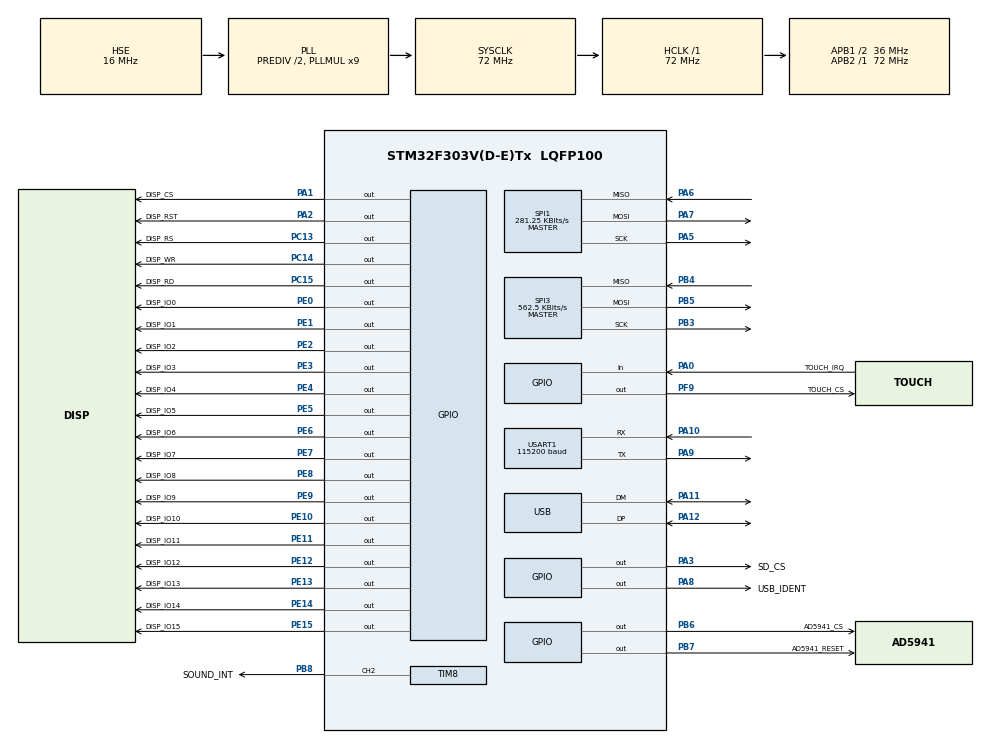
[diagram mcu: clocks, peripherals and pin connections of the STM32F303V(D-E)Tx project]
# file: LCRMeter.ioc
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ADC1.Channel-0\#ChannelRegularConversion=ADC_CHANNEL_VREFINT
ADC1.NbrOfConversionFlag=1
ADC1.Offset-0\#ChannelRegularConversion=0
ADC1.OffsetNumber-0\#ChannelRegularConversion=ADC_OFFSET_NONE
ADC1.Rank-0\#ChannelRegularConversion=1
ADC1.SamplingTime-0\#ChannelRegularConversion=ADC_SAMPLETIME_181CYCLES_5
ADC1.master=1
FREERTOS.MEMORY_ALLOCATION=2
FREERTOS.Tasks01=defaultTask,0,2048,StartDefaultTask,Default,NULL,Static,defaultTaskBuffer,defaultTaskControlBlock
FREERTOS.configTOTAL_HEAP_SIZE=35000
FREERTOS.configUSE_PREEMPTION=0
FREERTOS.configUSE_RECURSIVE_MUTEXES=1
Mcu.Family=STM32F3
Mcu.Name=STM32F303V(D-E)Tx
Mcu.Package=LQFP100
NVIC.PriorityGroup=NVIC_PRIORITYGROUP_4
NVIC.TIM6_DAC_IRQn=true\:0\:0\:false\:false\:true\:false\:false\:true
NVIC.TIM8_UP_IRQn=true\:1\:0\:true\:false\:true\:false\:true\:true
NVIC.TimeBase=TIM6_DAC_IRQn
NVIC.TimeBaseIP=TIM6
NVIC.USB_LP_CAN_RX0_IRQn=true\:5\:0\:false\:false\:true\:true\:false\:true
PA0.GPIO_Label=TOUCH_IRQ
PA0.Signal=GPIO_Input
PA1.GPIO_Label=DISP_CS
PA1.GPIO_Speed=GPIO_SPEED_FREQ_HIGH
PA1.PinState=GPIO_PIN_SET
PA1.Signal=GPIO_Output
PA10.Mode=Asynchronous
PA10.Signal=USART1_RX
PA11.Mode=Device
PA11.Signal=USB_DM
PA12.Mode=Device
PA12.Signal=USB_DP
PA13.Mode=Serial_Wire
PA13.Signal=SYS_JTMS-SWDIO
PA14.Mode=Serial_Wire
PA14.Signal=SYS_JTCK-SWCLK
PA2.GPIO_Label=DISP_RST
PA2.GPIO_Speed=GPIO_SPEED_FREQ_HIGH
PA2.Signal=GPIO_Output
PA3.GPIO_Label=SD_CS
PA3.GPIO_Speed=GPIO_SPEED_FREQ_HIGH
PA3.PinState=GPIO_PIN_SET
PA3.Signal=GPIO_Output
PA5.Mode=Full_Duplex_Master
PA5.Signal=SPI1_SCK
PA6.Mode=Full_Duplex_Master
PA6.Signal=SPI1_MISO
PA7.Mode=Full_Duplex_Master
PA7.Signal=SPI1_MOSI
PA8.GPIO_Label=USB_IDENT
PA8.GPIO_Speed=GPIO_SPEED_FREQ_LOW
PA8.Signal=GPIO_Output
PA9.Mode=Asynchronous
PA9.Signal=USART1_TX
PB3.Mode=Full_Duplex_Master
PB3.Signal=SPI3_SCK
PB4.Mode=Full_Duplex_Master
PB4.Signal=SPI3_MISO
PB5.Mode=Full_Duplex_Master
PB5.Signal=SPI3_MOSI
PB6.GPIO_Label=AD5941_CS
PB6.GPIO_Speed=GPIO_SPEED_FREQ_HIGH
PB6.PinState=GPIO_PIN_SET
PB6.Signal=GPIO_Output
PB7.GPIO_Label=AD5941_RESET
PB7.GPIO_Speed=GPIO_SPEED_FREQ_LOW
PB7.Signal=GPIO_Output
PB8.GPIO_Label=SOUND_INT
PB8.Signal=S_TIM8_CH2
PC13.GPIO_Label=DISP_RS
PC13.GPIO_Speed=GPIO_SPEED_FREQ_LOW
PC13.Signal=GPIO_Output
PC14-OSC32_IN.GPIO_Label=DISP_WR
PC14-OSC32_IN.GPIO_Speed=GPIO_SPEED_FREQ_LOW
PC14-OSC32_IN.Signal=GPIO_Output
PC15-OSC32_OUT.GPIO_Label=DISP_RD
PC15-OSC32_OUT.GPIO_Speed=GPIO_SPEED_FREQ_LOW
PC15-OSC32_OUT.Signal=GPIO_Output
PE0.GPIO_Label=DISP_IO0
PE0.GPIO_Speed=GPIO_SPEED_FREQ_HIGH
PE0.Signal=GPIO_Output
PE1.GPIO_Label=DISP_IO1
PE1.GPIO_Speed=GPIO_SPEED_FREQ_HIGH
PE1.Signal=GPIO_Output
PE10.GPIO_Label=DISP_IO10
PE10.GPIO_Speed=GPIO_SPEED_FREQ_HIGH
PE10.Signal=GPIO_Output
PE11.GPIO_Label=DISP_IO11
PE11.GPIO_Speed=GPIO_SPEED_FREQ_HIGH
PE11.Signal=GPIO_Output
PE12.GPIO_Label=DISP_IO12
PE12.GPIO_Speed=GPIO_SPEED_FREQ_HIGH
PE12.Signal=GPIO_Output
PE13.GPIO_Label=DISP_IO13
PE13.GPIO_Speed=GPIO_SPEED_FREQ_HIGH
PE13.Signal=GPIO_Output
PE14.GPIO_Label=DISP_IO14
PE14.GPIO_Speed=GPIO_SPEED_FREQ_HIGH
PE14.Signal=GPIO_Output
PE15.GPIO_Label=DISP_IO15
PE15.GPIO_Speed=GPIO_SPEED_FREQ_HIGH
PE15.Signal=GPIO_Output
PE2.GPIO_Label=DISP_IO2
PE2.GPIO_Speed=GPIO_SPEED_FREQ_HIGH
PE2.Signal=GPIO_Output
PE3.GPIO_Label=DISP_IO3
PE3.GPIO_Speed=GPIO_SPEED_FREQ_HIGH
PE3.Signal=GPIO_Output
PE4.GPIO_Label=DISP_IO4
PE4.GPIO_Speed=GPIO_SPEED_FREQ_HIGH
PE4.Signal=GPIO_Output
PE5.GPIO_Label=DISP_IO5
PE5.GPIO_Speed=GPIO_SPEED_FREQ_HIGH
PE5.Signal=GPIO_Output
PE6.GPIO_Label=DISP_IO6
PE6.GPIO_Speed=GPIO_SPEED_FREQ_HIGH
PE6.Signal=GPIO_Output
PE7.GPIO_Label=DISP_IO7
PE7.GPIO_Speed=GPIO_SPEED_FREQ_HIGH
PE7.Signal=GPIO_Output
PE8.GPIO_Label=DISP_IO8
PE8.GPIO_Speed=GPIO_SPEED_FREQ_HIGH
PE8.Signal=GPIO_Output
PE9.GPIO_Label=DISP_IO9
PE9.GPIO_Speed=GPIO_SPEED_FREQ_HIGH
PE9.Signal=GPIO_Output
PF0-OSC_IN.Mode=HSE-External-Oscillator
PF0-OSC_IN.Signal=RCC_OSC_IN
PF1-OSC_OUT.Mode=HSE-External-Oscillator
PF1-OSC_OUT.Signal=RCC_OSC_OUT
PF9.GPIO_Label=TOUCH_CS
PF9.GPIO_Speed=GPIO_SPEED_FREQ_HIGH
PF9.PinState=GPIO_PIN_SET
PF9.Signal=GPIO_Output
ProjectManager.HeapSize=0x200
ProjectManager.StackSize=0x400
ProjectManager.TargetToolchain=SW4STM32
RCC.AHBFreq_Value=72000000
RCC.APB1CLKDivider=RCC_HCLK_DIV2
RCC.APB1Freq_Value=36000000
RCC.APB1TimFreq_Value=72000000
RCC.APB2Freq_Value=72000000
RCC.APB2TimFreq_Value=72000000
RCC.CortexFreq_Value=72000000
RCC.HCLKFreq_Value=72000000
RCC.HSE_VALUE=16000000
RCC.HSI_VALUE=8000000
RCC.LSE_VALUE=32768
RCC.PLLDivider=RCC_PREDIV_DIV2
RCC.PLLMUL=RCC_PLL_MUL9
RCC.PRESCALERUSB=RCC_USBCLKSOURCE_PLL_DIV1_5
RCC.SYSCLKFreq_VALUE=72000000
RCC.SYSCLKSourceVirtual=RCC_SYSCLKSOURCE_PLLCLK
RCC.USBFreq_Value=48000000
SH.S_TIM8_CH2.0=TIM8_CH2,PWM Generation2 CH2
SPI1.BaudRatePrescaler=SPI_BAUDRATEPRESCALER_256
SPI1.CalculateBaudRate=281.25 KBits/s
SPI1.DataSize=SPI_DATASIZE_8BIT
SPI1.Direction=SPI_DIRECTION_2LINES
SPI1.Mode=SPI_MODE_MASTER
SPI1.VirtualType=VM_MASTER
SPI3.BaudRatePrescaler=SPI_BAUDRATEPRESCALER_64
SPI3.CalculateBaudRate=562.5 KBits/s
SPI3.DataSize=SPI_DATASIZE_8BIT
SPI3.Direction=SPI_DIRECTION_2LINES
SPI3.Mode=SPI_MODE_MASTER
SPI3.VirtualType=VM_MASTER
TIM8.Channel-PWM\ Generation2\ CH2=TIM_CHANNEL_2
TIM8.OCMode_PWM-PWM\ Generation2\ CH2=TIM_OCMODE_PWM1
TIM8.OCPolarity_2=TIM_OCPOLARITY_HIGH
TIM8.Period=999
TIM8.Prescaler=71
USART1.BaudRate=115200
USART1.VirtualMode-Asynchronous=VM_ASYNC
USB_DEVICE.CLASS_NAME_FS=CDC
USB_DEVICE.VirtualMode=Cdc
USB_DEVICE.VirtualModeFS=Cdc_FS
VP_ADC1_Vref_Input.Mode=IN-Vrefint
VP_FATFS_VS_Generic.Mode=User_defined
VP_FREERTOS_VS_CMSIS_V1.Mode=CMSIS_V1
VP_SYS_VS_tim6.Mode=TIM6
VP_TIM8_VS_ClockSourceINT.Mode=Internal
VP_USB_DEVICE_VS_USB_DEVICE_CDC_FS.Mode=CDC_FS
board=custom

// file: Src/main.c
/* USER CODE BEGIN Header */
/**
  ******************************************************************************
  * @file           : main.c
  * @brief          : Main program body
  ******************************************************************************
  * @attention
  *
  * <h2><center>&copy; Copyright (c) 2020 STMicroelectronics.
  * All rights reserved.</center></h2>
  *
  * This software component is licensed by ST under Ultimate Liberty license
  * SLA0044, the "License"; You may not use this file except in compliance with
  * the License. You may obtain a copy of the License at:
  *                             www.st.com/SLA0044
  *
  ******************************************************************************
  */
/* USER CODE END Header */

#include "main.h"
#include "cmsis_os.h"
#include "fatfs.h"
#include "usb_device.h"

ADC_HandleTypeDef hadc1;

SPI_HandleTypeDef hspi1;
SPI_HandleTypeDef hspi3;

TIM_HandleTypeDef htim8;

UART_HandleTypeDef huart1;

osThreadId defaultTaskHandle;
uint32_t defaultTaskBuffer[ 2048 ];
osStaticThreadDef_t defaultTaskControlBlock;

void SystemClock_Config(void);
static void MX_GPIO_Init(void);
static void MX_SPI1_Init(void);
static void MX_SPI3_Init(void);
static void MX_USART1_UART_Init(void);
static void MX_TIM8_Init(void);
static void MX_ADC1_Init(void);
void StartDefaultTask(void const * argument);

int main(void)
{

  /* MCU Configuration--------------------------------------------------------*/

  /* Reset of all peripherals, Initializes the Flash interface and the Systick. */
  HAL_Init();

  /* Configure the system clock */
  SystemClock_Config();

  /* Initialize all configured peripherals */
  MX_GPIO_Init();
  MX_SPI1_Init();
  MX_SPI3_Init();
  MX_USART1_UART_Init();
  MX_TIM8_Init();
  MX_ADC1_Init();
  /* USER CODE BEGIN 2 */
  HAL_Delay(100);
  display_Init();
  /* USER CODE END 2 */

  /* Create the thread(s) */
  /* definition and creation of defaultTask */
  osThreadStaticDef(defaultTask, StartDefaultTask, osPriorityNormal, 0, 2048, defaultTaskBuffer, &defaultTaskControlBlock);
  defaultTaskHandle = osThreadCreate(osThread(defaultTask), NULL);

  /* Start scheduler */
  osKernelStart();

  /* We should never get here as control is now taken by the scheduler */

  /* Infinite loop */
  while (1)
  {

  }
}

void SystemClock_Config(void)
{
  RCC_OscInitTypeDef RCC_OscInitStruct = {0};
  RCC_ClkInitTypeDef RCC_ClkInitStruct = {0};
  RCC_PeriphCLKInitTypeDef PeriphClkInit = {0};

  /** Initializes the CPU, AHB and APB busses clocks
  */
  RCC_OscInitStruct.OscillatorType = RCC_OSCILLATORTYPE_HSE;
  RCC_OscInitStruct.HSEState = RCC_HSE_ON;
  RCC_OscInitStruct.HSIState = RCC_HSI_ON;
  RCC_OscInitStruct.PLL.PLLState = RCC_PLL_ON;
  RCC_OscInitStruct.PLL.PLLSource = RCC_PLLSOURCE_HSE;
  RCC_OscInitStruct.PLL.PLLMUL = RCC_PLL_MUL9;
  RCC_OscInitStruct.PLL.PREDIV = RCC_PREDIV_DIV2;
  if (HAL_RCC_OscConfig(&RCC_OscInitStruct) != HAL_OK)
  {
    Error_Handler();
  }
  /** Initializes the CPU, AHB and APB busses clocks
  */
  RCC_ClkInitStruct.ClockType = RCC_CLOCKTYPE_HCLK|RCC_CLOCKTYPE_SYSCLK
                              |RCC_CLOCKTYPE_PCLK1|RCC_CLOCKTYPE_PCLK2;
  RCC_ClkInitStruct.SYSCLKSource = RCC_SYSCLKSOURCE_PLLCLK;
  RCC_ClkInitStruct.AHBCLKDivider = RCC_SYSCLK_DIV1;
  RCC_ClkInitStruct.APB1CLKDivider = RCC_HCLK_DIV2;
  RCC_ClkInitStruct.APB2CLKDivider = RCC_HCLK_DIV1;

  if (HAL_RCC_ClockConfig(&RCC_ClkInitStruct, FLASH_LATENCY_2) != HAL_OK)
  {
    Error_Handler();
  }
  PeriphClkInit.PeriphClockSelection = RCC_PERIPHCLK_USB|RCC_PERIPHCLK_USART1
                              |RCC_PERIPHCLK_TIM8|RCC_PERIPHCLK_ADC12;
  PeriphClkInit.Usart1ClockSelection = RCC_USART1CLKSOURCE_PCLK2;
  PeriphClkInit.Adc12ClockSelection = RCC_ADC12PLLCLK_DIV1;
  PeriphClkInit.USBClockSelection = RCC_USBCLKSOURCE_PLL_DIV1_5;
  PeriphClkInit.Tim8ClockSelection = RCC_TIM8CLK_HCLK;
  if (HAL_RCCEx_PeriphCLKConfig(&PeriphClkInit) != HAL_OK)
  {
    Error_Handler();
  }
}

static void MX_ADC1_Init(void)
{

  ADC_MultiModeTypeDef multimode = {0};
  ADC_ChannelConfTypeDef sConfig = {0};

  /** Common config
  */
  hadc1.Instance = ADC1;
  hadc1.Init.ClockPrescaler = ADC_CLOCK_ASYNC_DIV1;
  hadc1.Init.Resolution = ADC_RESOLUTION_12B;
  hadc1.Init.ScanConvMode = ADC_SCAN_DISABLE;
  hadc1.Init.ContinuousConvMode = DISABLE;
  hadc1.Init.DiscontinuousConvMode = DISABLE;
  hadc1.Init.ExternalTrigConvEdge = ADC_EXTERNALTRIGCONVEDGE_NONE;
  hadc1.Init.ExternalTrigConv = ADC_SOFTWARE_START;
  hadc1.Init.DataAlign = ADC_DATAALIGN_RIGHT;
  hadc1.Init.NbrOfConversion = 1;
  hadc1.Init.DMAContinuousRequests = DISABLE;
  hadc1.Init.EOCSelection = ADC_EOC_SINGLE_CONV;
  hadc1.Init.LowPowerAutoWait = DISABLE;
  hadc1.Init.Overrun = ADC_OVR_DATA_OVERWRITTEN;
  if (HAL_ADC_Init(&hadc1) != HAL_OK)
  {
    Error_Handler();
  }
  /** Configure the ADC multi-mode
  */
  multimode.Mode = ADC_MODE_INDEPENDENT;
  if (HAL_ADCEx_MultiModeConfigChannel(&hadc1, &multimode) != HAL_OK)
  {
    Error_Handler();
  }
  /** Configure Regular Channel
  */
  sConfig.Channel = ADC_CHANNEL_VREFINT;
  sConfig.Rank = ADC_REGULAR_RANK_1;
  sConfig.SingleDiff = ADC_SINGLE_ENDED;
  sConfig.SamplingTime = ADC_SAMPLETIME_181CYCLES_5;
  sConfig.OffsetNumber = ADC_OFFSET_NONE;
  sConfig.Offset = 0;
  if (HAL_ADC_ConfigChannel(&hadc1, &sConfig) != HAL_OK)
  {
    Error_Handler();
  }

}

static void MX_SPI1_Init(void)
{

  /* SPI1 parameter configuration*/
  hspi1.Instance = SPI1;
  hspi1.Init.Mode = SPI_MODE_MASTER;
  hspi1.Init.Direction = SPI_DIRECTION_2LINES;
  hspi1.Init.DataSize = SPI_DATASIZE_8BIT;
  hspi1.Init.CLKPolarity = SPI_POLARITY_LOW;
  hspi1.Init.CLKPhase = SPI_PHASE_1EDGE;
  hspi1.Init.NSS = SPI_NSS_SOFT;
  hspi1.Init.BaudRatePrescaler = SPI_BAUDRATEPRESCALER_256;
  hspi1.Init.FirstBit = SPI_FIRSTBIT_MSB;
  hspi1.Init.TIMode = SPI_TIMODE_DISABLE;
  hspi1.Init.CRCCalculation = SPI_CRCCALCULATION_DISABLE;
  hspi1.Init.CRCPolynomial = 7;
  hspi1.Init.CRCLength = SPI_CRC_LENGTH_DATASIZE;
  hspi1.Init.NSSPMode = SPI_NSS_PULSE_ENABLE;
  if (HAL_SPI_Init(&hspi1) != HAL_OK)
  {
    Error_Handler();
  }

}

static void MX_SPI3_Init(void)
{

  /* SPI3 parameter configuration*/
  hspi3.Instance = SPI3;
  hspi3.Init.Mode = SPI_MODE_MASTER;
  hspi3.Init.Direction = SPI_DIRECTION_2LINES;
  hspi3.Init.DataSize = SPI_DATASIZE_8BIT;
  hspi3.Init.CLKPolarity = SPI_POLARITY_LOW;
  hspi3.Init.CLKPhase = SPI_PHASE_1EDGE;
  hspi3.Init.NSS = SPI_NSS_SOFT;
  hspi3.Init.BaudRatePrescaler = SPI_BAUDRATEPRESCALER_64;
  hspi3.Init.FirstBit = SPI_FIRSTBIT_MSB;
  hspi3.Init.TIMode = SPI_TIMODE_DISABLE;
  hspi3.Init.CRCCalculation = SPI_CRCCALCULATION_DISABLE;
  hspi3.Init.CRCPolynomial = 7;
  hspi3.Init.CRCLength = SPI_CRC_LENGTH_DATASIZE;
  hspi3.Init.NSSPMode = SPI_NSS_PULSE_ENABLE;
  if (HAL_SPI_Init(&hspi3) != HAL_OK)
  {
    Error_Handler();
  }

}

static void MX_TIM8_Init(void)
{

  TIM_ClockConfigTypeDef sClockSourceConfig = {0};
  TIM_MasterConfigTypeDef sMasterConfig = {0};
  TIM_OC_InitTypeDef sConfigOC = {0};
  TIM_BreakDeadTimeConfigTypeDef sBreakDeadTimeConfig = {0};

  htim8.Instance = TIM8;
  htim8.Init.Prescaler = 71;
  htim8.Init.CounterMode = TIM_COUNTERMODE_UP;
  htim8.Init.Period = 999;
  htim8.Init.ClockDivision = TIM_CLOCKDIVISION_DIV1;
  htim8.Init.RepetitionCounter = 0;
  htim8.Init.AutoReloadPreload = TIM_AUTORELOAD_PRELOAD_DISABLE;
  if (HAL_TIM_Base_Init(&htim8) != HAL_OK)
  {
    Error_Handler();
  }
  sClockSourceConfig.ClockSource = TIM_CLOCKSOURCE_INTERNAL;
  if (HAL_TIM_ConfigClockSource(&htim8, &sClockSourceConfig) != HAL_OK)
  {
    Error_Handler();
  }
  if (HAL_TIM_PWM_Init(&htim8) != HAL_OK)
  {
    Error_Handler();
  }
  sMasterConfig.MasterOutputTrigger = TIM_TRGO_RESET;
  sMasterConfig.MasterOutputTrigger2 = TIM_TRGO2_RESET;
  sMasterConfig.MasterSlaveMode = TIM_MASTERSLAVEMODE_DISABLE;
  if (HAL_TIMEx_MasterConfigSynchronization(&htim8, &sMasterConfig) != HAL_OK)
  {
    Error_Handler();
  }
  sConfigOC.OCMode = TIM_OCMODE_PWM1;
  sConfigOC.Pulse = 0;
  sConfigOC.OCPolarity = TIM_OCPOLARITY_HIGH;
  sConfigOC.OCNPolarity = TIM_OCNPOLARITY_HIGH;
  sConfigOC.OCFastMode = TIM_OCFAST_DISABLE;
  sConfigOC.OCIdleState = TIM_OCIDLESTATE_RESET;
  sConfigOC.OCNIdleState = TIM_OCNIDLESTATE_RESET;
  if (HAL_TIM_PWM_ConfigChannel(&htim8, &sConfigOC, TIM_CHANNEL_2) != HAL_OK)
  {
    Error_Handler();
  }
  sBreakDeadTimeConfig.OffStateRunMode = TIM_OSSR_DISABLE;
  sBreakDeadTimeConfig.OffStateIDLEMode = TIM_OSSI_DISABLE;
  sBreakDeadTimeConfig.LockLevel = TIM_LOCKLEVEL_OFF;
  sBreakDeadTimeConfig.DeadTime = 0;
  sBreakDeadTimeConfig.BreakState = TIM_BREAK_DISABLE;
  sBreakDeadTimeConfig.BreakPolarity = TIM_BREAKPOLARITY_HIGH;
  sBreakDeadTimeConfig.BreakFilter = 0;
  sBreakDeadTimeConfig.Break2State = TIM_BREAK2_DISABLE;
  sBreakDeadTimeConfig.Break2Polarity = TIM_BREAK2POLARITY_HIGH;
  sBreakDeadTimeConfig.Break2Filter = 0;
  sBreakDeadTimeConfig.AutomaticOutput = TIM_AUTOMATICOUTPUT_DISABLE;
  if (HAL_TIMEx_ConfigBreakDeadTime(&htim8, &sBreakDeadTimeConfig) != HAL_OK)
  {
    Error_Handler();
  }
  HAL_TIM_MspPostInit(&htim8);

}

static void MX_USART1_UART_Init(void)
{

  huart1.Instance = USART1;
  huart1.Init.BaudRate = 115200;
  huart1.Init.WordLength = UART_WORDLENGTH_8B;
  huart1.Init.StopBits = UART_STOPBITS_1;
  huart1.Init.Parity = UART_PARITY_NONE;
  huart1.Init.Mode = UART_MODE_TX_RX;
  huart1.Init.HwFlowCtl = UART_HWCONTROL_NONE;
  huart1.Init.OverSampling = UART_OVERSAMPLING_16;
  huart1.Init.OneBitSampling = UART_ONE_BIT_SAMPLE_DISABLE;
  huart1.AdvancedInit.AdvFeatureInit = UART_ADVFEATURE_NO_INIT;
  if (HAL_UART_Init(&huart1) != HAL_OK)
  {
    Error_Handler();
  }

}

static void MX_GPIO_Init(void)
{
  GPIO_InitTypeDef GPIO_InitStruct = {0};

  /* GPIO Ports Clock Enable */
  __HAL_RCC_GPIOE_CLK_ENABLE();
  __HAL_RCC_GPIOC_CLK_ENABLE();
  __HAL_RCC_GPIOF_CLK_ENABLE();
  __HAL_RCC_GPIOA_CLK_ENABLE();
  __HAL_RCC_GPIOB_CLK_ENABLE();

  /*Configure GPIO pin Output Level */
  HAL_GPIO_WritePin(GPIOE, DISP_IO2_Pin|DISP_IO3_Pin|DISP_IO4_Pin|DISP_IO5_Pin
                          |DISP_IO6_Pin|DISP_IO7_Pin|DISP_IO8_Pin|DISP_IO9_Pin
                          |DISP_IO10_Pin|DISP_IO11_Pin|DISP_IO12_Pin|DISP_IO13_Pin
                          |DISP_IO14_Pin|DISP_IO15_Pin|DISP_IO0_Pin|DISP_IO1_Pin, GPIO_PIN_RESET);

  /*Configure GPIO pin Output Level */
  HAL_GPIO_WritePin(GPIOC, DISP_RS_Pin|DISP_WR_Pin|DISP_RD_Pin, GPIO_PIN_RESET);

  /*Configure GPIO pin Output Level */
  HAL_GPIO_WritePin(TOUCH_CS_GPIO_Port, TOUCH_CS_Pin, GPIO_PIN_SET);

  /*Configure GPIO pin Output Level */
  HAL_GPIO_WritePin(GPIOA, DISP_CS_Pin|SD_CS_Pin, GPIO_PIN_SET);

  /*Configure GPIO pin Output Level */
  HAL_GPIO_WritePin(GPIOA, DISP_RST_Pin|USB_IDENT_Pin, GPIO_PIN_RESET);

  /*Configure GPIO pin Output Level */
  HAL_GPIO_WritePin(AD5941_CS_GPIO_Port, AD5941_CS_Pin, GPIO_PIN_SET);

  /*Configure GPIO pin Output Level */
  HAL_GPIO_WritePin(AD5941_RESET_GPIO_Port, AD5941_RESET_Pin, GPIO_PIN_RESET);

  /*Configure GPIO pins : DISP_IO2_Pin DISP_IO3_Pin DISP_IO4_Pin DISP_IO5_Pin
                           DISP_IO6_Pin DISP_IO7_Pin DISP_IO8_Pin DISP_IO9_Pin
                           DISP_IO10_Pin DISP_IO11_Pin DISP_IO12_Pin DISP_IO13_Pin
                           DISP_IO14_Pin DISP_IO15_Pin DISP_IO0_Pin DISP_IO1_Pin */
  GPIO_InitStruct.Pin = DISP_IO2_Pin|DISP_IO3_Pin|DISP_IO4_Pin|DISP_IO5_Pin
                          |DISP_IO6_Pin|DISP_IO7_Pin|DISP_IO8_Pin|DISP_IO9_Pin
                          |DISP_IO10_Pin|DISP_IO11_Pin|DISP_IO12_Pin|DISP_IO13_Pin
                          |DISP_IO14_Pin|DISP_IO15_Pin|DISP_IO0_Pin|DISP_IO1_Pin;
  GPIO_InitStruct.Mode = GPIO_MODE_OUTPUT_PP;
  GPIO_InitStruct.Pull = GPIO_NOPULL;
  GPIO_InitStruct.Speed = GPIO_SPEED_FREQ_HIGH;
  HAL_GPIO_Init(GPIOE, &GPIO_InitStruct);

  /*Configure GPIO pins : DISP_RS_Pin DISP_WR_Pin DISP_RD_Pin */
  GPIO_InitStruct.Pin = DISP_RS_Pin|DISP_WR_Pin|DISP_RD_Pin;
  GPIO_InitStruct.Mode = GPIO_MODE_OUTPUT_PP;
  GPIO_InitStruct.Pull = GPIO_NOPULL;
  GPIO_InitStruct.Speed = GPIO_SPEED_FREQ_LOW;
  HAL_GPIO_Init(GPIOC, &GPIO_InitStruct);

  /*Configure GPIO pin : TOUCH_CS_Pin */
  GPIO_InitStruct.Pin = TOUCH_CS_Pin;
  GPIO_InitStruct.Mode = GPIO_MODE_OUTPUT_PP;
  GPIO_InitStruct.Pull = GPIO_NOPULL;
  GPIO_InitStruct.Speed = GPIO_SPEED_FREQ_HIGH;
  HAL_GPIO_Init(TOUCH_CS_GPIO_Port, &GPIO_InitStruct);

  /*Configure GPIO pin : TOUCH_IRQ_Pin */
  GPIO_InitStruct.Pin = TOUCH_IRQ_Pin;
  GPIO_InitStruct.Mode = GPIO_MODE_INPUT;
  GPIO_InitStruct.Pull = GPIO_NOPULL;
  HAL_GPIO_Init(TOUCH_IRQ_GPIO_Port, &GPIO_InitStruct);

  /*Configure GPIO pins : DISP_CS_Pin DISP_RST_Pin SD_CS_Pin */
  GPIO_InitStruct.Pin = DISP_CS_Pin|DISP_RST_Pin|SD_CS_Pin;
  GPIO_InitStruct.Mode = GPIO_MODE_OUTPUT_PP;
  GPIO_InitStruct.Pull = GPIO_NOPULL;
  GPIO_InitStruct.Speed = GPIO_SPEED_FREQ_HIGH;
  HAL_GPIO_Init(GPIOA, &GPIO_InitStruct);

  /*Configure GPIO pin : USB_IDENT_Pin */
  GPIO_InitStruct.Pin = USB_IDENT_Pin;
  GPIO_InitStruct.Mode = GPIO_MODE_OUTPUT_PP;
  GPIO_InitStruct.Pull = GPIO_NOPULL;
  GPIO_InitStruct.Speed = GPIO_SPEED_FREQ_LOW;
  HAL_GPIO_Init(USB_IDENT_GPIO_Port, &GPIO_InitStruct);

  /*Configure GPIO pin : AD5941_CS_Pin */
  GPIO_InitStruct.Pin = AD5941_CS_Pin;
  GPIO_InitStruct.Mode = GPIO_MODE_OUTPUT_PP;
  GPIO_InitStruct.Pull = GPIO_NOPULL;
  GPIO_InitStruct.Speed = GPIO_SPEED_FREQ_HIGH;
  HAL_GPIO_Init(AD5941_CS_GPIO_Port, &GPIO_InitStruct);

  /*Configure GPIO pin : AD5941_RESET_Pin */
  GPIO_InitStruct.Pin = AD5941_RESET_Pin;
  GPIO_InitStruct.Mode = GPIO_MODE_OUTPUT_PP;
  GPIO_InitStruct.Pull = GPIO_NOPULL;
  GPIO_InitStruct.Speed = GPIO_SPEED_FREQ_LOW;
  HAL_GPIO_Init(AD5941_RESET_GPIO_Port, &GPIO_InitStruct);

}

/* USER CODE BEGIN 4 */
#include "Start.h"
/* USER CODE END 4 */

void StartDefaultTask(void const * argument)
{
  /* init code for USB_DEVICE */
  MX_USB_DEVICE_Init();

  /* init code for FATFS */
  MX_FATFS_Init();

  /* USER CODE BEGIN 5 */
  Start();
  /* Infinite loop */
  for(;;)
  {
    osDelay(1);
  }
  /* USER CODE END 5 */
}

void HAL_TIM_PeriodElapsedCallback(TIM_HandleTypeDef *htim)
{
  if (htim->Instance == TIM6) {
    HAL_IncTick();
  }
}

void Error_Handler(void)
{
}

/************************ (C) COPYRIGHT STMicroelectronics *****END OF FILE****/

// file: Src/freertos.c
/* USER CODE BEGIN Header */
/**
  ******************************************************************************
  * File Name          : freertos.c
  * Description        : Code for freertos applications
  ******************************************************************************
  * @attention
  *
  * <h2><center>&copy; Copyright (c) 2020 STMicroelectronics.
  * All rights reserved.</center></h2>
  *
  * This software component is licensed by ST under Ultimate Liberty license
  * SLA0044, the "License"; You may not use this file except in compliance with
  * the License. You may obtain a copy of the License at:
  *                             www.st.com/SLA0044
  *
  ******************************************************************************
  */
/* USER CODE END Header */

#include "FreeRTOS.h"
#include "task.h"
#include "main.h"

/* GetIdleTaskMemory prototype (linked to static allocation support) */
void vApplicationGetIdleTaskMemory( StaticTask_t **ppxIdleTaskTCBBuffer, StackType_t **ppxIdleTaskStackBuffer, uint32_t *pulIdleTaskStackSize );

/* USER CODE BEGIN GET_IDLE_TASK_MEMORY */
static StaticTask_t xIdleTaskTCBBuffer;
static StackType_t xIdleStack[configMINIMAL_STACK_SIZE];

void vApplicationGetIdleTaskMemory( StaticTask_t **ppxIdleTaskTCBBuffer, StackType_t **ppxIdleTaskStackBuffer, uint32_t *pulIdleTaskStackSize )
{
  *ppxIdleTaskTCBBuffer = &xIdleTaskTCBBuffer;
  *ppxIdleTaskStackBuffer = &xIdleStack[0];
  *pulIdleTaskStackSize = configMINIMAL_STACK_SIZE;
  /* place for user code */
}
/* USER CODE END GET_IDLE_TASK_MEMORY */

/************************ (C) COPYRIGHT STMicroelectronics *****END OF FILE****/
